# MM32F3270 register map
File version: 3.01
CPU: CM3 r2p1, selectable endian, MPU, no FPU, 3 interrupt priority bits
Registers are 32-bit, read-write, reset 0x0 unless marked. A register's access mark holds for its fields unless they carry their own. Offsets are from the block's base; [hi:lo] are bit positions; {n}, {i} and the like mark numbered series.

## TIM3 — General purpose timer
Base 0x40000400
Same registers: TIM4 0x40000800
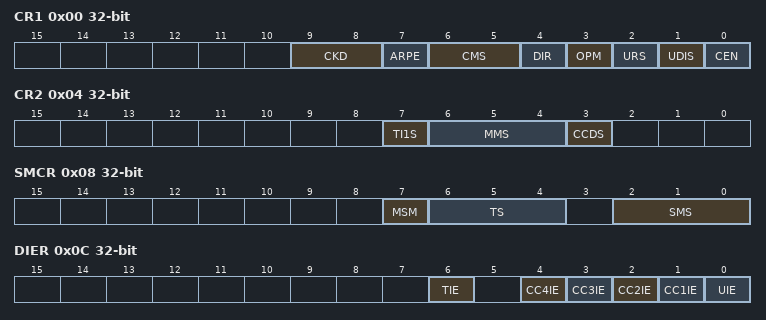
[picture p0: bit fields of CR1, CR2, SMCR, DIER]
0x00 CR1 — control register 1
  [9:8] CKD — Clock division
  [7] ARPE — Auto-reload preload enable
  [6:5] CMS — Center-aligned mode selection
  [4] DIR — Direction
  [3] OPM — One pulse mode
  [2] URS — Update request source
  [1] UDIS — Update disable
  [0] CEN — Counter enable
0x04 CR2 — control register 2
  [7] TI1S — TI1 selection
  [6:4] MMS — Master mode selection
  [3] CCDS — Capture/Compare DMA selection
0x08 SMCR — slave mode control register 1
  [7] MSM — Master/slave mode
  [6:4] TS — Trigger selection
  [2:0] SMS — Slave mode selection
0x0C DIER — DMA/Interrupt enable register
  [6] TIE — Trigger interrupt enable
  [n] CC{n}IE (n=1..4) — Capture/Compare {n} interrupt enable
  [0] UIE — Update interrupt enable
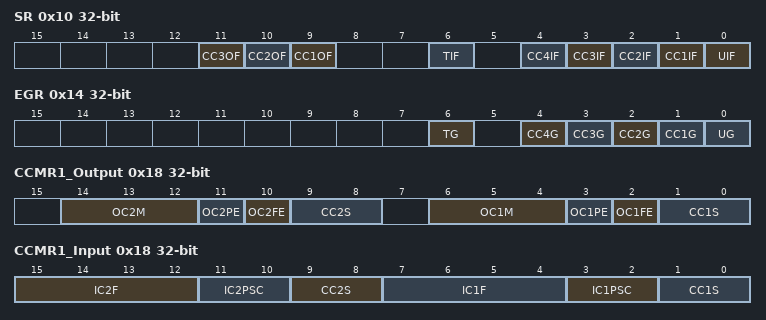
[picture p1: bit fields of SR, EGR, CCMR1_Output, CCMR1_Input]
0x10 SR write-0-clears — status register
  [11] CC3OF — Capture/Compare 3 overcapture flag
  [10] CC2OF — Capture/Compare 2 overcapture flag
  [9] CC1OF — Capture/Compare 1 overcapture flag
  [6] TIF — Trigger interrupt flag
  [n] CC{n}IF (n=1..4) — Capture/Compare {n} interrupt flag
  [0] UIF — Update interrupt flag
0x14 EGR wo — event generation register
  [6] TG — Trigger generation
  [n] CC{n}G (n=1..4) — Capture/compare {n} generation
  [0] UG — Update generation
0x18 CCMR1_Output — capture/compare mode register 1 (output mode)
  [14:12] OC2M — Output compare 2 mode
  [11] OC2PE — Output compare 2 preload enable
  [10] OC2FE — Output compare 4 fast enable
  [9:8] CC2S — Capure/Compare 2 selection
  [6:4] OC1M — Output compare 1 mode
  [3] OC1PE — Output compare 1 preload enable
  [2] OC1FE — Output compare 1 fast enable
  [1:0] CC1S — Capture/Compare 2 output enable
0x18 CCMR1_Input (alternate view of CCMR1_Output) — capture/compare mode register 1 (input mode)
  [15:12] IC2F — Input capture 2 filter
  [11:10] IC2PSC — Input capture 2 prescaler
  [9:8] CC2S — Capture/Compare 2 selection
  [7:4] IC1F — Input capture 1 filter
  [3:2] IC1PSC — Input capture 1 prescaler
  [1:0] CC1S — Capture/compare 1 selection
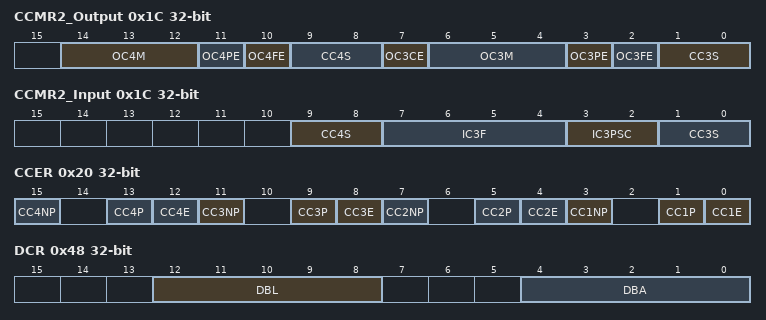
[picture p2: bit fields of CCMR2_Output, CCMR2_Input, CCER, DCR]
0x1C CCMR2_Output — capture/compare mode register 2(output mode)
  [14:12] OC4M — Output compare 4 mode
  [11] OC4PE — Output compare 4 preload enable
  [10] OC4FE — Output compare 4 fast enable
  [9:8] CC4S — Capture/Compare 4 selection
  [7] OC3CE — Output compare 3 clear enable
  [6:4] OC3M — Output compare 3 mode
  [3] OC3PE — Output compare 3 preload enable
  [2] OC3FE — Output compare 3 fast enable
  [1:0] CC3S — Capture/Compare 3 selection
0x1C CCMR2_Input (alternate view of CCMR2_Output) — capture/compare mode register 2 (input mode)
  [9:8] CC4S — Capture/Compare 4 selection
  [7:4] IC3F — Input capture 3 filter
  [3:2] IC3PSC — Input capture 3 prescaler
  [1:0] CC3S — Capture/compare 3 selection
0x20 CCER — capture/compare enable register
  [4n-1] CC{n}NP (n=1..4) — Capture/Compare {n} complementary output polarity
  [4n-3] CC{n}P (n=1..4) — Capture/Compare {n} output polarity
  [4n-4] CC{n}E (n=1..4) — Capture/Compare {n} output enable
0x24 CNT — counter
  [15:0] CNT — Counter value
0x28 PSC — prescaler
  [15:0] PSC — Prescaler value
0x2C ARR — auto-reload register
  [15:0] ARR — Auto reload value
{0x30+4i} CCR{i} (i=1..4) — capture/compare register {i}
  [15:0] CCR{i} — Capture/Compare {i} value
0x48 DCR wo — DMA control register
  [12:8] DBL — DMA burst length
  [4:0] DBA — DMA base address
0x4C DMAR wo — DMA address for full transfer
  [15:0] DMAB — DMA register for burst accesses

## TIM6 — Basic purpose timer
Base 0x40001000
Same registers: TIM7 0x40001400
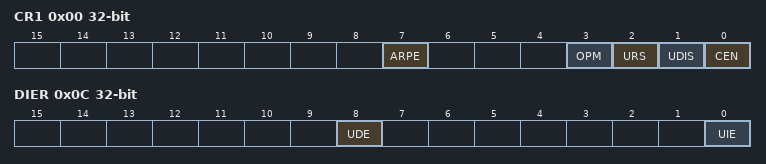
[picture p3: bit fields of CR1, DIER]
0x00 CR1 — control register 1
  [7] ARPE — Auto-reload preload enable
  [3] OPM — One pulse mode
  [2] URS — Update request source
  [1] UDIS — Update disable
  [0] CEN — Counter enable
0x0C DIER — DMA/Interrupt enable register
  [8] UDE — Update DMA request enable
  [0] UIE — Update interrupt enable
0x10 SR write-0-clears — status register
  [0] UIF — *D0
0x14 EGR wo — event generation register
  [0] UG — *D0
0x24 CNT — counter
  [15:0] CNT — Counter value
0x28 PSC — prescaler
  [15:0] PSC — Prescaler value
0x2C ARR — auto-reload register
  [15:0] ARR — Auto reload value

## WWDG — Window watchdog
Base 0x40002C00
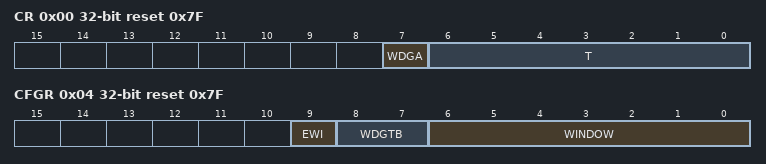
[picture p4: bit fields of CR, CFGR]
0x00 CR reset 0x7F — Control register
  [7] WDGA — Activation bit
  [6:0] T — 7-bit counter
0x04 CFGR reset 0x7F — Configuration register
  [9] EWI — Early wakeup interrupt
  [8:7] WDGTB — Timer base
  [6:0] WINDOW — 7-bit window value
0x08 SR — Status register
  [0] EWIF write-0-clears — Early wakeup interrupt flag
